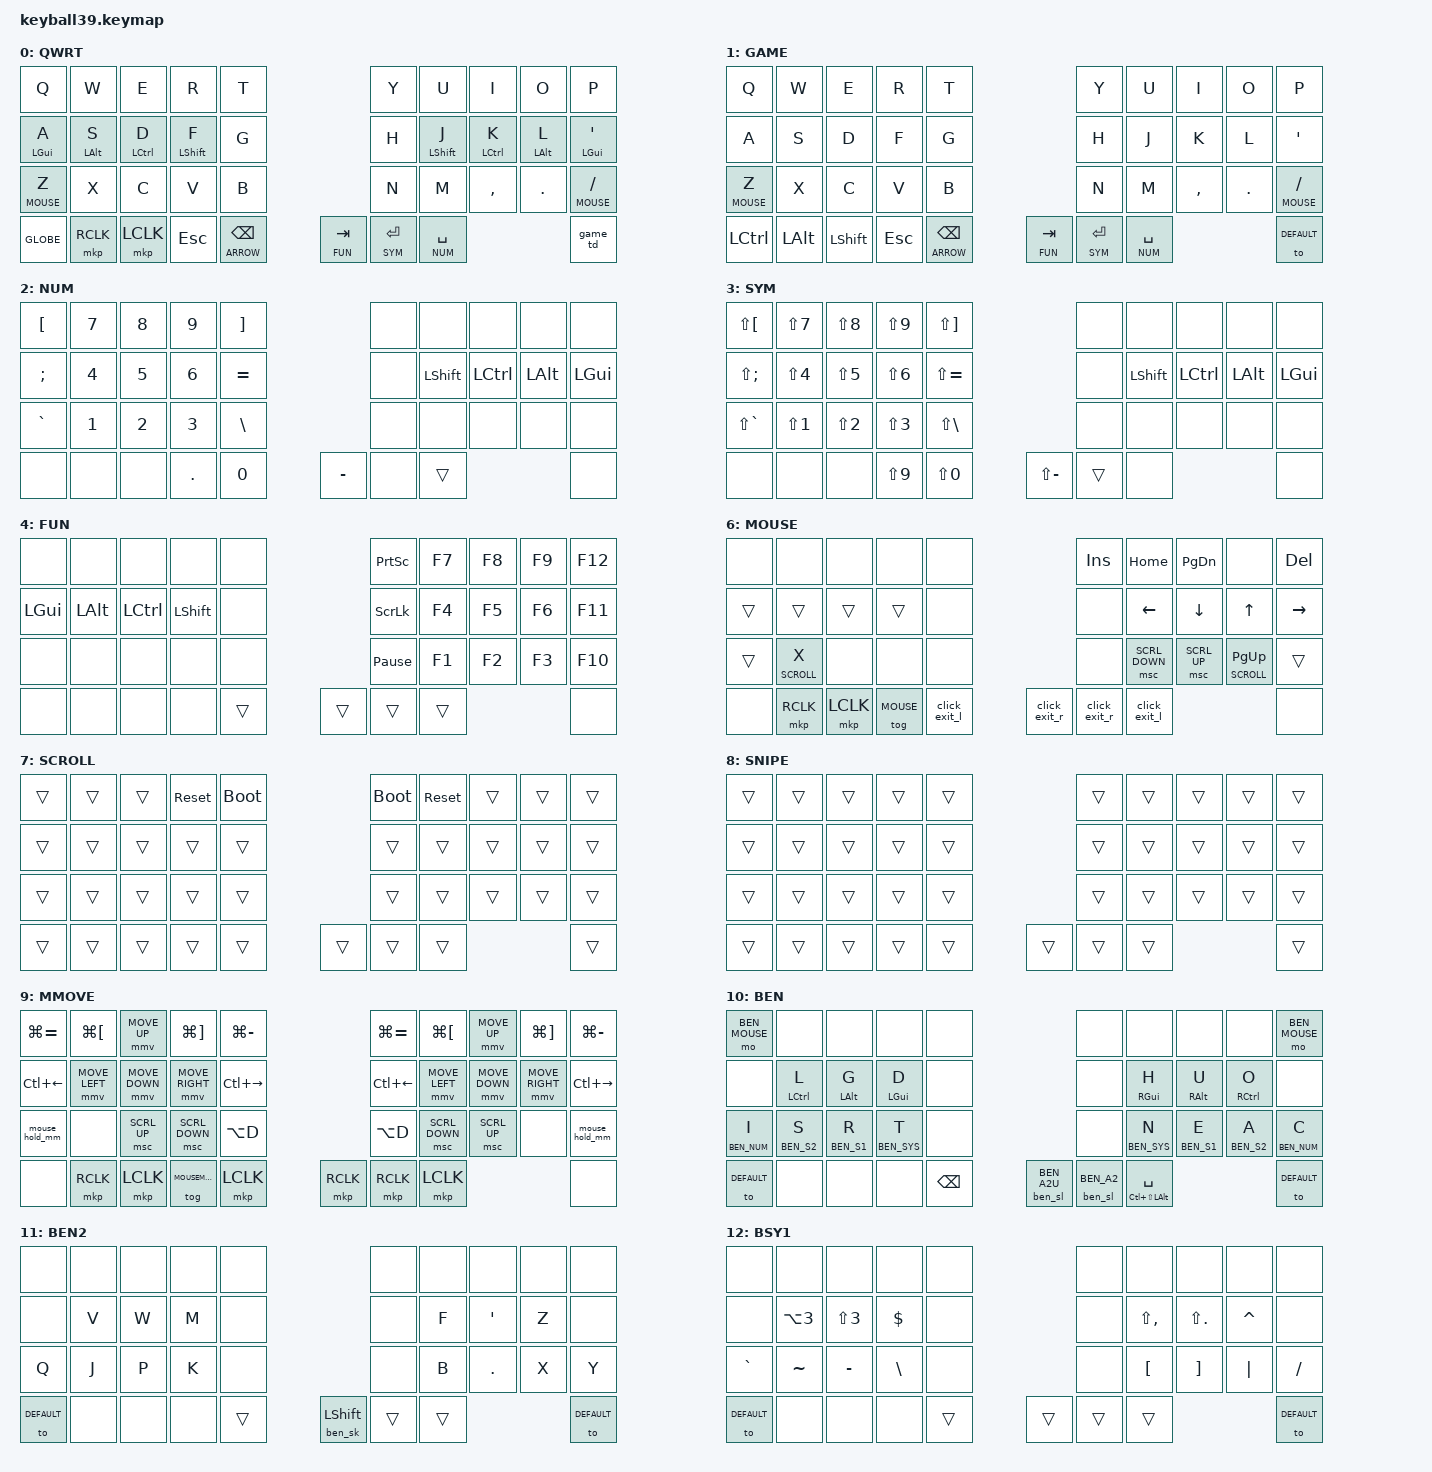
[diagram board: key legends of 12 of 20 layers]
#define DEFAULT 0
#define GAME    1
#define NUM     2
#define SYM     3
#define FUN     4
#define ARROW   5
#define MOUSE   6
#define SCROLL  7
#define SNIPE   8
#define MOUSEMOVE 9

// ── Ben Vallack "Piano" profile ────────────────────────────────────────
// A complete 18-key alternative layout living on layers 10-17, ported
// from benvallack/zmk-config-piano. It uses only 7 finger keys per hand
// (left S D F Z X C V, right J K L M , . /) plus 4 thumbs; every other
// position is &none so nothing bleeds through from QWRT.
//
// The alphabet is SPLIT: the 14 commonest letters (etaoinsrhldcug — ~85%
// of English) sit on BEN itself, the remaining 12 on BEN_A2, reached by
// a sticky-layer tap of the right outer thumb. Sub-layers are held from
// the bottom row exactly as Ben has them.
//
// Enter: triple-tap position 38. Exit: single tap of 38 (or 30).
#define BEN      10   // alpha1  — the 14 common letters + homerow mods
#define BEN_A2   11   // alpha2  — the 12 rare letters, via sticky layer
#define BEN_S1   12   // sym1    — hold C / ,
#define BEN_S2   13   // sym2    — hold X / .
#define BEN_NUM  14   // num     — hold Z / /
#define BEN_SYS  15   // sys     — hold V / M  (nav, editing, clicks)
#define BEN_BT   16   // bt      — bluetooth + &bootloader
#define BEN_A2U  17   // alpha2 shifted — capitals of the rare letters
#define BEN_MOUSE 18  // mouse    — hold Q / P, or the Q+W / O+P chord
#define BEN_SCRL  19  // scroll   — from BEN_MOUSE, hold W / O

// NOTE: BEN_SCRL is duplicated as a #define in keyball39_right.overlay,
// where it is listed in the trackball's scroll-layers. The two must stay
// in sync — the overlay cannot see this file's defines.

// Override max mouse cursor speed for &mmv (default 600 — tuned for 4K).
// Bumped from 1500 → 2100 (+40%) to match Delta Omega's "big-monitor
// reach" tuning. Drop back to 1500/600 if too fast. Must precede
// <dt-bindings/zmk/pointing.h>.
#define ZMK_POINTING_DEFAULT_MOVE_VAL 2100

// &msc scroll magnitude per tick (ZMK default 10).
//
// Was 20, which made Safari jump rather than scroll. The old comment here
// claimed CONFIG_ZMK_POINTING_SMOOTH_SCROLLING would render this
// high-resolution and let macOS smooth it. That is not what the code does,
// so the magnitude has to be right on its own:
//
//   1. zmk/app/src/pointing/resolution_multipliers.c defaults the wheel
//      multiplier to 15, and input_listener.c computes div = 16 - wheel.
//      15 -> div == 1, i.e. NO scaling at all unless the host negotiates a
//      different multiplier via a HID Feature report.
//   2. apply_resolution_scaling() in input_listener.c computes the divided
//      value and then discards it:
//          int16_t scaled = val / (int16_t)div;
//          *remainder = val - (scaled * (int16_t)div);
//          evt->value = val;      // <- unscaled; `scaled` is dead
//      So even with a cooperating host it never attenuates. Upstream ZMK,
//      not this config.
//
// SCRL_VAL is WHEEL EVENTS PER SECOND, not a magnitude. behavior_input_two_axis.c
// accumulates speed * trigger_period_ms/1000 per tick and emits only when the
// accumulator crosses 1.0, so the emitted value is always +/-1 and the rate is
// exactly SCRL_VAL.
//
// That matters because macOS supplies the smoothing itself, via
// IOHIDScrollAccelerator::accelerate() — a polynomial in the INTER-EVENT GAP:
//     8ms -> 1.386    16ms -> 1.276    50ms -> 0.849    125ms -> 0.156
// ~815x collapse from 1ms to 150ms spacing. So event RATE is the whole game:
// closely spaced events get accelerated and blended into a glide, widely
// spaced ones are rendered as bare individual notches.
//
// Retuned for the patched HID descriptor. With macOS computing a scroll
// resolution of 85 instead of its 9.0 fallback, one wheel unit moves
// 9/85 as far — about 0.32 lines instead of 3. That is the whole point: the
// STEP is now ~9.4x finer, which is what smoothness actually is. Speed has to
// be bought back by raising the rate to match, since speed = rate x step.
//
//   before:  60 units/sec x 3.00 lines = 180 lines/sec, in 3-line steps
//   after:  552 units/sec x 0.32 lines = 175 lines/sec, in 0.32-line steps
//
// 552 is the user's requested +15% over the 480 that first felt right.
// trigger-period-ms below caps EVENT emission at 1000/period = 500/sec, so
// above 500 a fraction of ticks carry 2 units rather than 1. At 0.32 lines
// per unit that worst-case step is 0.64 lines — still 4.7x finer than the
// 3-line step we had before the descriptor fix, so the cost is negligible.
//
// CAVEAT — USB vs BLE. 480 reports/sec is comfortable over USB. Over BLE at
// the 7.5ms connection interval in keyball39.conf the practical ceiling is
// nearer 133/sec, so wireless scrolling will be roughly a quarter this speed.
// If that bites, raise the connection interval or accept a slower wireless
// scroll — the smoothness is unaffected either way, only the speed.
#define ZMK_POINTING_DEFAULT_SCRL_VAL 552

#include <behaviors/mouse_keys.dtsi>
#include <dt-bindings/zmk/mouse.h>
#include <behaviors.dtsi>
#include <dt-bindings/zmk/keys.h>
#include <dt-bindings/zmk/bt.h>
#include <dt-bindings/zmk/pointing.h>
#include <input/processors.dtsi>

// Layer-taps: matches QMK LT() defaults on the Charybdis (tap-preferred
// semantics, 200ms term, 200ms quick-tap-repeat).
&lt {
    tapping-term-ms = <200>;
    flavor = "tap-preferred";
    quick-tap-ms = <200>;
};

// Default &mt override. NOTE: the home-row mods do NOT use &mt — they use
// the dedicated hm_* hold-taps below. This block only affects any bare
// `&mt` bindings (currently none). DANGER averted: stock ZMK &mt is
// hold-preferred (fires mod on next keypress — the opposite of the
// Charybdis feel), so this override pins it to the same Charybdis-parity
// values as the hm_* behaviors in case a bare &mt is ever added.
&mt {
    tapping-term-ms = <200>;
    flavor = "tap-preferred";
    quick-tap-ms = <200>;
};

&msc {
    // These two only do anything because SMOOTH_SCROLLING is off — with it on,
    // get_acceleration_exponent() force-returns 0 for the wheel axes and
    // speed() short-circuits to max_speed. See keyball39_right.conf.
    acceleration-exponent = <1>;  // linear ramp in, then constant
    // Ease-in for held scrolling. exponent 1 is LINEAR: speed = max * t/ttms,
    // starting from ZERO — ZMK has no floor parameter, so you cannot say
    // "start at 70%". A longer ramp therefore buys ease-in at the cost of
    // lead-in, because the accumulator must still reach 1.0 before the first
    // detent is emitted, at T = sqrt(2*ttms/SCRL_VAL).
    //
    // The scale here is SECONDS, not milliseconds. 40/150/200ms all felt
    // identical — a fifth of a second is below the threshold of noticing, so
    // scrolling appeared to start at full speed no matter what. Full speed is
    // 60 detents/sec, roughly 180 lines/sec at the macOS default of 3
    // lines/detent, so a 300ms "tap" at ttms=200 was already covering a page.
    //
    //   ttms   1st detent   detents by 0.2s / 0.4s / 1.0s / 2.0s
    //    200      82 ms        6.0 / 18.0 / 54.0 / 114.0   (felt instant)
    //   1500     224 ms        0.8 /  3.2 / 20.0 /  75.0   <- here
    //
    // Deliberate consequence: a press SHORTER THAN ~224ms now emits nothing
    // at all, because cumulative counts are max*T^2/(2*ttms) and that is
    // below 1.0. A flick no longer jumps the page; it does nothing. Scrolling
    // is now something you hold, not something you tap. If short taps need to
    // work again, lower this — the lead-in falls as sqrt(ttms).
    time-to-max-speed-ms = <1500>;
    // 2ms. The ceiling on emitted events is 1000/trigger-period, so 8ms
    // capped us at 125/sec — far below the 480/sec the finer step size now
    // needs. NB this Mac reports HIDMouseScrollAcceleration = 0, so macOS
    // applies a single linear segment rather than its gap-based accelerator
    // curve; rate buys smoothness directly here, not via OS acceleration.
    trigger-period-ms = <2>;
    delay-ms = <0>;
};

// Keyboard-driven mouse cursor (&mmv MOVE_* on the MOUSE layer).
// Defaults from urob/zmk-config — gentle ramp for fine control.
// Knobs:
//   acceleration-exponent: 0=constant speed, 1=quadratic (smooth), higher=more aggressive
//   time-to-max-speed-ms:  higher = more precision on short taps, lower = snappier traversal
//   delay-ms:              dead time before motion starts (keep 0)
// Max speed itself is set by ZMK_POINTING_DEFAULT_MOVE_VAL (default 600);
// override with `#define ZMK_POINTING_DEFAULT_MOVE_VAL <n>` before pointing.h
// if you find max traversal too slow/fast for your display resolution.
&mmv {
    acceleration-exponent = <1>;
    time-to-max-speed-ms = <500>;
    delay-ms = <0>;
};

&caps_word { continue-list = <UNDERSCORE MINUS>; };

/ {
    // custom shift using mod-morph

    combos {
        compatible = "zmk,combos";

        // Toggle the MOUSEMOVE layer with a two-finger chord.
        // Restricted to <DEFAULT MOUSEMOVE> so a stray S+D / K+L on
        // other layers (NUM, SYM, ARROW, etc.) doesn't fire &tog
        // MOUSEMOVE — same defensive pattern Delta Omega's TODO calls
        // out around combo layer-filter interference.
        // Left hand: S + D. Right hand: K + L.
        // NOTE: on MMOVE, S and D are MOVE_LEFT / MOVE_DOWN. A deliberate
        // simultaneous S+D tap exits the layer; normal diagonal movement
        // (press S, then add D >25ms later, holding) does not.
        combo_sd_mmove {
            timeout-ms = <25>;
            require-prior-idle-ms = <250>;
            key-positions = <11 12>; // S + D
            bindings = <&tog MOUSEMOVE>;
            layers = <DEFAULT MOUSEMOVE>;
        };
        combo_right_mousemove {
            timeout-ms = <25>;
            require-prior-idle-ms = <250>;
            key-positions = <17 18>; // K + L
            bindings = <&tog MOUSEMOVE>;
            layers = <DEFAULT MOUSEMOVE>;
        };

        // Lock MOUSE on via one-handed two-finger chord. Restricted to
        // <DEFAULT MOUSE> for the same reason as the MOUSEMOVE combos.
        // Z and / are already &lt MOUSE — holding momentarily activates
        // MOUSE; the combo is the "stay there" path. Click bindings on
        // MOUSE call &tog MOUSE (via the click_exit_* macros) so
        // clicking exits the lock.
        combo_left_mouse {
            timeout-ms = <25>;
            require-prior-idle-ms = <250>;
            key-positions = <20 21>; // Z + X
            bindings = <&tog MOUSE>;
            layers = <DEFAULT MOUSE>;
        };
        combo_right_mouse {
            timeout-ms = <25>;
            require-prior-idle-ms = <250>;
            key-positions = <28 29>; // . + /
            bindings = <&tog MOUSE>;
            layers = <DEFAULT MOUSE>;
        };
        // Same chords FROM MMOVE: lock MOUSE on and drop MMOVE
        // underneath, so when MOUSE later exits (click / ESC-position)
        // you land on QWRT, not back in MMOVE. Mirrors the QWRT-side
        // muscle memory (Z+X / .+/) inside the mouse-move layer.
        combo_left_mouse_mm {
            timeout-ms = <25>;
            require-prior-idle-ms = <250>;
            key-positions = <20 21>; // Z + X (on MMOVE)
            bindings = <&mouse_lock_mm>;
            layers = <MOUSEMOVE>;
        };
        combo_right_mouse_mm {
            timeout-ms = <25>;
            require-prior-idle-ms = <250>;
            key-positions = <28 29>; // . + / (on MMOVE)
            bindings = <&mouse_lock_mm>;
            layers = <MOUSEMOVE>;
        };

        // Horizontal scroll chords on MMOVE — 4 directions from 3 keys
        // per hand. Rule: "lean the pair toward the direction":
        //   left hand:  X+C = scroll left,  C+V = scroll right
        //   right hand: M+, = scroll left,  ,+. = scroll right
        // Hold the chord to keep scrolling (same as the 3-finger
        // combos). No require-prior-idle — MMOVE is a nav layer, no
        // typing rolls to guard against, and an idle gate would block
        // chording right after a vertical scroll. 50ms window for an
        // easy deliberate two-finger press. (Copy/paste X+C / C+V
        // combos are QWRT-only now; on MMOVE these positions scroll.
        // X+V cut, D+F del, A+S select-all still work on MMOVE.)
        combo_hscroll_left_l {
            timeout-ms = <50>;
            key-positions = <21 22>; // X + C (on MMOVE)
            bindings = <&msc SCRL_LEFT>;
            layers = <MOUSEMOVE>;
        };
        combo_hscroll_right_l {
            timeout-ms = <50>;
            key-positions = <22 23>; // C + V (on MMOVE)
            bindings = <&msc SCRL_RIGHT>;
            layers = <MOUSEMOVE>;
        };
        combo_hscroll_left_r {
            timeout-ms = <50>;
            key-positions = <26 27>; // M + , (on MMOVE)
            bindings = <&msc SCRL_LEFT>;
            layers = <MOUSEMOVE>;
        };
        combo_hscroll_right_r {
            timeout-ms = <50>;
            key-positions = <27 28>; // , + . (on MMOVE)
            bindings = <&msc SCRL_RIGHT>;
            layers = <MOUSEMOVE>;
        };

        // Three-finger scroll combos, active on QWRT and MMOVE. Looser
        // 50ms window than the 2-key combos — a 3-key chord is harder
        // to land simultaneously, and rolling three specific keys
        // mid-typing is unlikely, so the wider window is safe.
        // require-prior-idle-ms 250 still blocks it during a typing
        // burst. Held: all three keys down keeps &msc scrolling;
        // release any one to stop. Both hands, mirrored:
        //   right: U+I+O up, M+,+. down
        //   left:  W+E+R up, X+C+V down
        // NOTE: X+C+V is a superset of the copy/paste/cut 2-key combos,
        // so those pick up ~50ms standalone activation latency (the
        // resolver waits out X+C+V's candidacy window). Accepted
        // tradeoff. W+E+R has no such overlap.
        combo_scroll_up {
            timeout-ms = <50>;
            require-prior-idle-ms = <250>;
            key-positions = <6 7 8>;     // U + I + O
            bindings = <&msc SCRL_UP>;
            layers = <DEFAULT>;
        };
        combo_scroll_down {
            timeout-ms = <50>;
            require-prior-idle-ms = <250>;
            key-positions = <26 27 28>;  // M + , + .
            bindings = <&msc SCRL_DOWN>;
            layers = <DEFAULT>;
        };
        combo_scroll_up_left {
            timeout-ms = <50>;
            require-prior-idle-ms = <250>;
            key-positions = <1 2 3>;     // W + E + R
            bindings = <&msc SCRL_UP>;
            layers = <DEFAULT>;
        };
        combo_scroll_down_left {
            timeout-ms = <50>;
            require-prior-idle-ms = <250>;
            key-positions = <21 22 23>;  // X + C + V
            bindings = <&msc SCRL_DOWN>;
            layers = <DEFAULT>;
        };

        // Two-key action combos. 25ms window (the standard 2-key combo
        // timing here) + require-prior-idle-ms 250 so they can't fire
        // mid-typing-burst.
        //   - ESC combos (Q+W, J+K): DEFAULT only.
        //   - Editing combos (D+F del, A+S select-all, X+C copy,
        //     C+V paste, X+V cut): DEFAULT + MOUSEMOVE, so they're
        //     reachable while in the mouse-move layer too.
        //
        // J+K consistently fires ESC across DEFAULT and MMOVE — two
        // combos with the same positions, one per layer. Ported from
        // Delta Omega: the MMOVE variant USED to fire &tog MOUSEMOVE
        // (combo_exit_mmove_jk), but having J+K mean two different
        // things on different layers was inconsistent. Exit MMOVE via
        // S+D or K+L combos, or the ESC-position thumb key.
        combo_esc_qw {
            timeout-ms = <25>;
            require-prior-idle-ms = <250>;
            key-positions = <0 1>;       // Q + W
            bindings = <&kp ESC>;
            layers = <DEFAULT>;
        };
        combo_esc_jk {
            timeout-ms = <25>;
            require-prior-idle-ms = <250>;
            key-positions = <16 17>;     // J + K
            bindings = <&kp ESC>;
            layers = <DEFAULT>;
        };
        combo_esc_mmove_jk {
            timeout-ms = <25>;
            require-prior-idle-ms = <250>;
            key-positions = <16 17>;     // J + K (on MMOVE → also ESC)
            bindings = <&kp ESC>;
            layers = <MOUSEMOVE>;
        };
        combo_del_df {
            timeout-ms = <25>;
            require-prior-idle-ms = <250>;
            key-positions = <12 13>;     // D + F
            bindings = <&kp DEL>;
            layers = <DEFAULT MOUSEMOVE>;
        };
        // Select-all (Cmd+A) on A+S. Both A+S and S+D are subsets of
        // the A+S+D caps_word combo — the resolver still picks the
        // 2-key combo correctly when the 3rd key isn't pressed, but
        // with ~50ms latency (it waits out caps_word's candidacy
        // window). Acceptable: neither is speed-critical, and pressing
        // all of A+S+D fires caps_word cleanly.
        combo_select_all_as {
            timeout-ms = <25>;
            require-prior-idle-ms = <250>;
            key-positions = <10 11>;     // A + S
            bindings = <&kp LG(A)>;
            layers = <DEFAULT MOUSEMOVE>;
        };
        combo_copy_xc {
            timeout-ms = <25>;
            require-prior-idle-ms = <250>;
            key-positions = <21 22>;     // X + C
            bindings = <&kp LG(C)>;
            layers = <DEFAULT>;
        };
        combo_paste_cv {
            timeout-ms = <25>;
            require-prior-idle-ms = <250>;
            key-positions = <22 23>;     // C + V
            bindings = <&kp LG(V)>;
            layers = <DEFAULT>;
        };
        combo_cut_xv {
            timeout-ms = <25>;
            require-prior-idle-ms = <250>;
            key-positions = <21 23>;     // X + V
            bindings = <&kp LG(X)>;
            layers = <DEFAULT MOUSEMOVE>;
        };

        // Three-key caps-word combo. A+S+D — position 10 (A) is unique
        // to this combo, so there's no subset/superset ambiguity with
        // any other combo. 50ms window (the >2-key standard here).
        // Fires &caps_word: the next word is shifted, auto-ends on
        // space/most punctuation (continue-list keeps it through - and _).
        combo_caps_word {
            timeout-ms = <50>;
            require-prior-idle-ms = <250>;
            key-positions = <10 11 12>;  // A + S + D
            bindings = <&caps_word>;
            layers = <DEFAULT>;
        };

        // === Ben "Piano" profile combos ===
        // Every one is gated to a BEN_* layer. ZMK matches a combo's
        // `layers` list against the HIGHEST active layer, so a combo
        // gated to BEN is automatically suppressed while a BEN sub-layer
        // is held — which is exactly what Ben's config relies on.
        ben_combo_sys {
            timeout-ms = <30>;
            key-positions = <16 17 18>;   // J + K + L
            bindings = <&to BEN_SYS>;
            layers = <BEN>;
        };
        ben_combo_caps {
            timeout-ms = <30>;
            key-positions = <26 27 28>;   // M + , + .
            bindings = <&caps_word>;
            layers = <BEN>;
        };
        // Escape hatch to the BT/bootloader layer: hold C (SYM1), then
        // chord , + . — this is the reflash path while living in BEN.
        ben_combo_bt {
            timeout-ms = <10>;
            key-positions = <27 28>;      // , + .
            bindings = <&to BEN_BT>;
            layers = <BEN_S1>;
        };
        // Mouse toggle from BEN. Z+X and .+/ are real letters here
        // (i+s and a+c), so the chord moves up to the unused top row —
        // same shape, same hands, one row higher.
        ben_combo_mouse_l {
            timeout-ms = <25>;
            require-prior-idle-ms = <250>;
            key-positions = <0 1>;        // Q + W
            bindings = <&tog BEN_MOUSE>;
            layers = <BEN>;
        };
        ben_combo_mouse_r {
            timeout-ms = <25>;
            require-prior-idle-ms = <250>;
            key-positions = <8 9>;        // O + P
            bindings = <&tog BEN_MOUSE>;
            layers = <BEN>;
        };
        // Horizontal scroll inside the Ben profile, identical in shape to the
        // MMOVE chords so there is only one thing to remember: the shared
        // middle key is the pivot and the neighbour you add picks the
        // direction. Z and SLASH stay clear as the layer escape.
        ben_combo_hscroll_left_l {
            timeout-ms = <50>;
            key-positions = <21 22>;      // X + C
            bindings = <&msc SCRL_LEFT>;
            layers = <BEN_MOUSE>;
        };
        ben_combo_hscroll_right_l {
            timeout-ms = <50>;
            key-positions = <22 23>;      // C + V
            bindings = <&msc SCRL_RIGHT>;
            layers = <BEN_MOUSE>;
        };
        ben_combo_hscroll_left_r {
            timeout-ms = <50>;
            key-positions = <26 27>;      // M + ,
            bindings = <&msc SCRL_LEFT>;
            layers = <BEN_MOUSE>;
        };
        ben_combo_hscroll_right_r {
            timeout-ms = <50>;
            key-positions = <27 28>;      // , + .
            bindings = <&msc SCRL_RIGHT>;
            layers = <BEN_MOUSE>;
        };
        ben_combo_lalt {
            timeout-ms = <20>;
            key-positions = <22 23>;      // C + V
            bindings = <&kp LALT>;
            layers = <BEN_SYS>;
        };
        ben_combo_lclk {
            timeout-ms = <20>;
            key-positions = <26 27>;      // M + ,
            bindings = <&mkp LCLK>;
            layers = <BEN_SYS>;
        };
        ben_combo_rclk {
            timeout-ms = <20>;
            key-positions = <16 17>;      // J + K
            bindings = <&mkp RCLK>;
            layers = <BEN_SYS>;
        };

    };

    behaviors {
        // === Home row mods — CHARYBDIS PARITY (QMK-default port) ===
        // The user's Charybdis Nano (QMK bkb-master @ 0.24.7, keymap
        // "cdmap") runs 100% stock QMK tap-hold: TAPPING_TERM 200,
        // QUICK_TAP_TERM 200, no PERMISSIVE_HOLD, no HOLD_ON_OTHER_KEY_
        // PRESS, no chordal/positional anything. Its feel — which the
        // user calls "absolutely spot on, perfect" — is ONE rule on
        // every finger:
        //
        //   Hold the key past 200ms -> modifier (any letters pressed in
        //   the meantime are queued and come out WITH the mod).
        //   Release before 200ms -> letters. Release order, roll
        //   direction, typing flow: all irrelevant. Pure timer.
        //
        // ZMK equivalent (verified line-by-line against QMK
        // action_tapping.c and ZMK behavior_hold_tap.c): flavor =
        // "tap-preferred", tapping-term-ms 200, quick-tap-ms 200, NO
        // require-prior-idle-ms, NO hold-trigger-key-positions, NO
        // hold-trigger-on-release. The earlier per-finger flavor mix +
        // 280-300ms terms + idle gates + cross-hand lists were the
        // source of "takes too long" / "missed capitals" / inconsistent
        // feel: the lists outright forced same-hand capitals (F held +
        // R) and same-hand chords (A held + C = Cmd+C) to TAP unless
        // the mod was held ALONE first, and the mixed flavors meant no
        // single muscle-memory rule worked everywhere.
        //
        // Capitals under parity: press F, press the letter any time,
        // keep F down until 200ms from F-down -> capital (the letter is
        // captured and replayed shifted). Same as the Charybdis.
        //
        // TWO deliberate non-parity islands (explicit user requests):
        //   hm_lalt (L): keeps a positions list of everything-except-D,
        //     so an L+D overlap inside the decision window can't fire
        //     Alt+D (= macOS dictation; the deliberate voice key lives
        //     on MMOVE). Hold L alone past 200ms then D still works.
        //   hm_apos ('): stays balanced + thumbs-only list + rpi 150 so
        //     '+Space = Cmd+Space (Spotlight) fires INSTANTLY on Space
        //     release, while '+letter can never mod (contractions safe).
        //
        // Tuning dial if mid-word linger-mods ever materialize: add
        // require-prior-idle-ms <100-150> to the NON-shift mods only
        // (QMK can't express it, but it only acts mid-burst). Ship
        // strict parity first.

        // S (LALT), D (LCTRL) — left hand.
        hm_l: home_row_mod_left {
            compatible = "zmk,behavior-hold-tap";
            #binding-cells = <2>;
            flavor = "tap-preferred";
            tapping-term-ms = <200>;
            quick-tap-ms = <200>;
            bindings = <&kp>, <&kp>;
        };
        // A (LGUI) — left pinky.
        hm_a: home_row_mod_a {
            compatible = "zmk,behavior-hold-tap";
            #binding-cells = <2>;
            flavor = "tap-preferred";
            tapping-term-ms = <200>;
            quick-tap-ms = <200>;
            // Veto list: every position EXCEPT 18 (L). Mirror of hm_lalt's
            // everything-except-D list (which blocks Alt+D dictation).
            //
            // Why: rolling "al" (all, also, always, total...) with A held past
            // the 200ms term resolved A as GUI, and GUI+L on the user's RDP'd
            // Windows box is Win+L — instant session lock. With 18 omitted,
            // an L that arrives while A is still undecided FORBIDS the hold,
            // so it resolves as tap and emits the literal "al" instead.
            //
            // A veto can only cancel holds, never create them, so every other
            // GUI chord (Cmd+S, Cmd+C, Win+anything) is unaffected. Deliberate
            // Cmd+L (macOS address bar) still works: hold A alone past 200ms
            // FIRST, then tap L — by then the hold is already decided and the
            // list is never consulted.
            //
            // Do NOT add hold-trigger-on-release here: with tap-preferred the
            // decision fires on the timer, before releases are processed, so
            // on-release leaves position_of_first_other_key_pressed at -1 and
            // silently defeats this list (bitten by this before).
            hold-trigger-key-positions = <0 1 2 3 4 5 6 7 8 9 10 11 12 13 14 15 16 17 19 20 21 22 23 24 25 26 27 28 29 30 31 32 33 34 35 36 37 38>;
            bindings = <&kp>, <&kp>;
        };
        // K (LCTRL) — right hand.
        hm_r: home_row_mod_right {
            compatible = "zmk,behavior-hold-tap";
            #binding-cells = <2>;
            flavor = "tap-preferred";
            tapping-term-ms = <200>;
            quick-tap-ms = <200>;
            bindings = <&kp>, <&kp>;
        };
        // L (LALT) — non-parity island #1: list = everything except D
        // (pos 12) so an L+D overlap in the window can't fire Alt+D
        // (dictation). See header comment.
        hm_lalt: home_row_mod_l_alt {
            compatible = "zmk,behavior-hold-tap";
            #binding-cells = <2>;
            flavor = "tap-preferred";
            tapping-term-ms = <200>;
            quick-tap-ms = <200>;
            hold-trigger-key-positions = <0 1 2 3 4 5 6 7 8 9 10 11 13 14 15 16 17 18 19 20 21 22 23 24 25 26 27 28 29 30 31 32 33 34 35 36 37 38>;
            bindings = <&kp>, <&kp>;
        };
        // ' (LGUI) — non-parity island #2: balanced + a curated list.
        // Listed keys resolve Cmd INSTANTLY (on the key's release, like
        // Spotlight); everything else is forced to tap. List = thumbs
        // (30-38, '+Space Spotlight) + the left-hand edit cluster the
        // user chords through ' all day:
        //   10=A select-all, 13=F find, 20=Z undo, 21=X cut,
        //   22=C copy, 23=V paste
        // These are the letters that (almost) never follow an apostrophe
        // in English. The real contraction letters stay OUT and can
        // never mod: S('s), T('t), D('d), R/E('re), M('m), L('ll).
        // Edge words ("I've", "o'clock", "y'all") are still protected
        // in-flow by require-prior-idle-ms 150 — mid-word, ' is forced
        // to tap before the list is even consulted.
        hm_apos: home_row_mod_apos {
            compatible = "zmk,behavior-hold-tap";
            #binding-cells = <2>;
            flavor = "balanced";
            tapping-term-ms = <200>;
            quick-tap-ms = <200>;
            require-prior-idle-ms = <150>;
            hold-trigger-on-release;
            hold-trigger-key-positions = <10 13 20 21 22 23 30 31 32 33 34 35 36 37 38>;
            bindings = <&kp>, <&kp>;
        };
        // F, J (LSHFT) — same tap-preferred timer as the other mods but
        // with a PER-FINGER shorter term: 170ms instead of 200.
        // Rationale: the user hits shift very rapidly and was releasing
        // F/J just before the 200ms mark -> "fi" instead of "I".
        // Index fingers are the fastest fingers; sunaku's Glorious
        // Engrammer ships index=180 on tap-preferred; user opted one
        // notch below. 170 rescues releases in the 170-200ms band
        // where the misses live.
        // Tuning ladder if "fi" persists: 160 next, 150 is the hard
        // floor (below that, a slow deliberate 'f' letter-tap starts
        // registering as Shift and plain letters get dropped).
        hm_shift_l: hm_shift_left {
            compatible = "zmk,behavior-hold-tap";
            #binding-cells = <2>;
            flavor = "tap-preferred";
            tapping-term-ms = <170>;
            quick-tap-ms = <200>;
            bindings = <&kp>, <&kp>;
        };
        hm_shift_r: hm_shift_right {
            compatible = "zmk,behavior-hold-tap";
            #binding-cells = <2>;
            flavor = "tap-preferred";
            tapping-term-ms = <170>;
            quick-tap-ms = <200>;
            bindings = <&kp>, <&kp>;
        };

        // GAME-layer entry guarded by double-tap. Position 38 was firing
        // accidentally from palm/pinky brushes — single tap now no-ops,
        // two taps within 250ms enter GAME. Exit (in game_layer) is still
        // single-tap so leaving the layer is friction-free.
        game_td: game_tap_dance {
            compatible = "zmk,behavior-tap-dance";
            #binding-cells = <0>;
            tapping-term-ms = <250>;
            bindings = <&none>, <&to GAME>, <&to BEN>;
        };

        // === Ben "Piano" profile behaviors ===
        // Verbatim timings from benvallack/zmk-config-piano, kept in
        // their own ben_* namespace so the Charybdis-parity tuning on
        // the QWRT homerow mods above is left completely alone.
        //
        // NB hold-tap parameter order is <hold>, <tap> — so
        // `&ben_td Q BSPC` is hold=Q, TAP=backspace.
        ben_hm_l: ben_homerow_mod_left {
            compatible = "zmk,behavior-hold-tap";
            #binding-cells = <2>;
            tapping-term-ms = <300>;
            quick-tap-ms = <250>;
            flavor = "tap-preferred";
            bindings = <&kp>, <&kp>;
        };
        ben_hm_r: ben_homerow_mod_right {
            compatible = "zmk,behavior-hold-tap";
            #binding-cells = <2>;
            tapping-term-ms = <300>;
            quick-tap-ms = <250>;
            flavor = "tap-preferred";
            bindings = <&kp>, <&kp>;
        };
        ben_hl_l: ben_homerow_layer_left {
            compatible = "zmk,behavior-hold-tap";
            #binding-cells = <2>;
            tapping-term-ms = <220>;
            quick-tap-ms = <250>;
            flavor = "tap-preferred";
            bindings = <&mo>, <&kp>;
        };
        ben_hl_r: ben_homerow_layer_right {
            compatible = "zmk,behavior-hold-tap";
            #binding-cells = <2>;
            tapping-term-ms = <220>;
            quick-tap-ms = <250>;
            flavor = "tap-preferred";
            bindings = <&mo>, <&kp>;
        };
        // hold = shift, tap = jump back to the BEN alpha layer.
        ben_sr: ben_shift_layer {
            compatible = "zmk,behavior-hold-tap";
            #binding-cells = <2>;
            tapping-term-ms = <300>;
            quick-tap-ms = <0>;
            flavor = "tap-preferred";
            bindings = <&kp>, <&to>;
            retro-tap;
        };
        ben_td: ben_tapdance {
            compatible = "zmk,behavior-hold-tap";
            #binding-cells = <2>;
            tapping-term-ms = <190>;
            quick-tap-ms = <250>;
            flavor = "tap-preferred";
            bindings = <&kp>, <&kp>;
        };
        // Local sticky key so Ben's 2s window doesn't mutate the global
        // &sk that the QWRT profile may want later.
        ben_sk: ben_sticky_key {
            compatible = "zmk,behavior-sticky-key";
            #binding-cells = <1>;
            bindings = <&kp>;
            release-after-ms = <2000>;
            quick-release;
        };
        // Sticky LAYER for the alpha2 hop. Stock &sl expires after
        // 1000ms; that is fine once the layout is in muscle memory but
        // brutal while learning — overrun the window and the sticky
        // layer has already dropped, so you silently get the alpha1
        // letter instead of the alpha2 one you meant. 2000ms matches the
        // window Ben picked for his own sticky key. Drop it back to
        // 1000 once the layout is fluent.
        ben_sl: ben_sticky_layer {
            compatible = "zmk,behavior-sticky-key";
            #binding-cells = <1>;
            bindings = <&mo>;
            release-after-ms = <2000>;
            quick-release;
        };
    };

    macros {
        // Click-and-exit-MOUSE macros.
        //
        // MOUSE is entered explicitly (hold Z/SLASH via &lt, or the
        // z+x / .+/ combos which &tog it on). These macros make clicks
        // terminal: send the click, hold it for the duration the key is
        // held (so drag works), and on release fire &tog MOUSE to drop
        // the layer. Combined with the combos, the model is "enter →
        // act → click exits."
        click_exit_l: click_exit_left {
            compatible = "zmk,behavior-macro";
            #binding-cells = <0>;
            bindings
                = <&macro_press &mkp LCLK>
                , <&macro_pause_for_release>
                , <&macro_release &mkp LCLK>
                , <&tog MOUSE>
                ;
        };
        click_exit_r: click_exit_right {
            compatible = "zmk,behavior-macro";
            #binding-cells = <0>;
            bindings
                = <&macro_press &mkp RCLK>
                , <&macro_pause_for_release>
                , <&macro_release &mkp RCLK>
                , <&tog MOUSE>
                ;
        };

        // MMOVE -> MOUSE handoff keys (bound on MMOVE Z and /).
        // Hold: drop out of MMOVE, momentarily activate MOUSE; on
        // release, fall through to QWRT — mirroring the QWRT-side
        // "hold Z / hold SLASH for MOUSE" muscle memory from inside
        // the mouse-move layer. A quick tap = exit MMOVE to QWRT
        // (brief MOUSE blip, harmless).
        mouse_hold_mm: mouse_hold_from_mmove {
            compatible = "zmk,behavior-macro";
            #binding-cells = <0>;
            bindings
                = <&macro_tap &tog MOUSEMOVE>
                , <&macro_press &mo MOUSE>
                , <&macro_pause_for_release>
                , <&macro_release &mo MOUSE>
                ;
        };
        // Z+X / .+/ chord from MMOVE: lock MOUSE on and turn MMOVE
        // off underneath — exiting MOUSE later (click / ESC-position)
        // lands on QWRT.
        mouse_lock_mm: mouse_lock_from_mmove {
            compatible = "zmk,behavior-macro";
            #binding-cells = <0>;
            bindings = <&macro_tap &tog MOUSEMOVE &tog MOUSE>;
        };
    };

    keymap {
        compatible = "zmk,keymap";

        default_layer {
            label = "QWRT";
            bindings = <
&kp Q       &kp W       &kp E        &kp R        &kp T                                    &kp Y          &kp U          &kp I        &kp O       &kp P
&hm_a LGUI A  &hm_l LALT S  &hm_l LCTRL D  &hm_shift_l LSHFT F  &kp G                        &kp H  &hm_shift_r LSHFT J  &hm_r LCTRL K  &hm_lalt LALT L  &hm_apos LGUI APOS
&lt MOUSE Z &kp X       &kp C        &kp V        &kp B                                    &kp N          &kp M          &kp COMMA    &kp DOT     &lt MOUSE SLASH
&kp GLOBE   &mkp RCLK   &mkp LCLK    &kp ESC      &lt ARROW BACKSPACE  &lt FUN TAB         &lt SYM ENTER  &lt NUM SPACE                           &game_td
            >;
        };

        game_layer {
            label = "GAME";
            bindings = <
&kp Q         &kp W     &kp E        &kp R        &kp T                                    &kp Y          &kp U          &kp I        &kp O       &kp P
&kp A         &kp S     &kp D        &kp F        &kp G                                    &kp H          &kp J          &kp K        &kp L       &kp APOS
&lt MOUSE Z   &kp X     &kp C        &kp V        &kp B                                    &kp N          &kp M          &kp COMMA    &kp DOT     &lt MOUSE SLASH
&kp LCTRL     &kp LALT  &kp LSHFT    &kp ESC      &lt ARROW BACKSPACE  &lt FUN TAB         &lt SYM ENTER  &lt NUM SPACE                           &to DEFAULT
            >;
        };

        number_layer {
            label = "NUM";
            bindings = <
&kp LEFT_BRACKET  &kp NUMBER_7  &kp NUMBER_8  &kp NUMBER_9  &kp RIGHT_BRACKET                    &none   &none      &none      &none     &none
&kp SEMI          &kp NUMBER_4  &kp NUMBER_5  &kp NUMBER_6  &kp EQUAL                            &none   &kp LSHFT  &kp LCTRL  &kp LALT  &kp LGUI
&kp GRAVE         &kp NUMBER_1  &kp NUMBER_2  &kp NUMBER_3  &kp BACKSLASH                        &none   &none      &none      &none     &none
&none             &none         &none         &kp PERIOD    &kp NUMBER_0   &kp MINUS             &none  &trans                           &none
            >;
        };

        symbol_layer {
            label = "SYM";
            bindings = <
&kp LS(LEFT_BRACKET)  &kp LS(NUMBER_7)  &kp LS(NUMBER_8)  &kp LS(NUMBER_9)  &kp LS(RIGHT_BRACKET)                         &none  &none      &none      &none     &none
&kp LS(SEMI)          &kp LS(NUMBER_4)  &kp LS(NUMBER_5)  &kp LS(NUMBER_6)  &kp LS(EQUAL)                                 &none  &kp LSHFT  &kp LCTRL  &kp LALT  &kp LGUI
&kp LS(GRAVE)         &kp LS(NUMBER_1)  &kp LS(NUMBER_2)  &kp LS(NUMBER_3)  &kp LS(BACKSLASH)                             &none  &none      &none      &none     &none
&none                 &none             &none             &kp LS(NUMBER_9)  &kp LS(NUMBER_0)       &kp LS(MINUS)          &trans &none                           &none
            >;
        };

        function_layer {
            label = "FUN";
            bindings = <
&none     &none     &none      &none      &none                 &kp PRINTSCREEN  &kp F7  &kp F8  &kp F9  &kp F12
&kp LGUI  &kp LALT  &kp LCTRL  &kp LSHFT  &none                 &kp SCROLLLOCK   &kp F4  &kp F5  &kp F6  &kp F11
&none     &none     &none      &none      &none                 &kp PAUSE_BREAK  &kp F1  &kp F2  &kp F3  &kp F10
&none     &none     &none      &none      &trans  &trans        &trans           &trans                  &none
            >;
        };

        arrow_layer {
            label = "ARROW";
            bindings = <
&trans    &trans               &trans     &trans              &bt BT_CLR             &bt BT_SEL 0  &bt BT_SEL 1  &bt BT_SEL 2  &bt BT_SEL 3  &bt BT_SEL 4
&kp LGUI  &kp LALT             &kp LCTRL  &kp LSHFT           &none                  &kp LEFT      &kp LEFT      &kp DOWN      &kp UP        &kp RIGHT
&trans    &kp K_VOLUME_DOWN    &kp K_MUTE &kp K_VOLUME_UP     &kp LC(LS(LA(LG(M))))  &kp INS       &kp HOME      &kp PG_DN     &kp PG_UP     &kp END
&trans    &trans               &trans     &trans              &trans  &trans         &trans  &trans                                          &trans
            >;
        };

        mouse_layer {
            label = "MOUSE";
            bindings = <
&none   &none   &none   &none      &none                            &kp INS    &kp HOME      &kp PAGE_DOWN  &none               &kp DEL
&trans  &trans  &trans  &trans     &none                            &none      &kp LEFT      &kp DOWN       &kp UP              &kp RIGHT
&trans  &lt SCROLL X  &none   &none      &none                       &none      &msc SCRL_DOWN  &msc SCRL_UP  &lt SCROLL PAGE_UP  &trans
&none   &mkp RCLK  &mkp LCLK  &tog MOUSE  &click_exit_l  &click_exit_r     &click_exit_r  &click_exit_l                     &none
            >;
        };

        scroll_layer {
            label = "SCROLL";
            bindings = <
&trans    &trans  &trans  &sys_reset  &bootloader          &bootloader   &sys_reset  &trans  &trans  &trans
&trans    &trans  &trans  &trans     &trans               &trans        &trans     &trans  &trans  &trans
&trans    &trans  &trans  &trans     &trans               &trans        &trans     &trans  &trans  &trans
&trans    &trans  &trans  &trans     &trans      &trans   &trans        &trans                     &trans
            >;
        };

        snipe_layer {
            label = "SNIPE";
            bindings = <
&trans  &trans  &trans  &trans  &trans                       &trans  &trans  &trans  &trans  &trans
&trans  &trans  &trans  &trans  &trans                       &trans  &trans  &trans  &trans  &trans
&trans  &trans  &trans  &trans  &trans                       &trans  &trans  &trans  &trans  &trans
&trans  &trans  &trans  &trans  &trans &trans                &trans  &trans                  &trans
            >;
        };

        // Two-handed keyboard mouse layer. Entered/exited via combos:
        //   left hand:  S + D together (after 250ms idle, 25ms timeout)
        //   right hand: K + L together (same)
        //   also exits: the ESC-position thumb key
        // (J + K on MMOVE now fires ESC, matching its DEFAULT behavior —
        // ported from Delta Omega for cross-layer consistency.)
        // Inverted-T movement clusters on each hand:
        //   left:  E=up, S=left, D=down, F=right
        //   right: I=up, J=left, K=down, L=right
        // Vertical scroll (bottom row, finger-natural — middle=up, index=down):
        //   left:  C=scroll up,  V=scroll down
        //   right: M=scroll down, ,=scroll up
        // MOUSE handoff (mirrors QWRT muscle memory, see mouse_hold_mm):
        //   hold Z or / = momentary MOUSE, release -> QWRT
        //   Z+X or .+/ chord = lock MOUSE, exit lands on QWRT
        // Horizontal scroll — chorded on the 3 vertical-scroll keys,
        // "lean the pair toward the direction" (see combos block):
        //   left hand:  X+C = left, C+V = right (C/V singles = up/down)
        //   right hand: M+, = left, ,+. = right (,/M singles = up/down)
        // App content zoom (Cmd+= / Cmd+-):
        //   Q and Y  = zoom in
        //   T and P  = zoom out
        // Was Cmd+Opt+= / Cmd+Opt+-, the macOS Accessibility screen
        // magnifier, which needed a System Settings opt-in and blew up
        // the whole display. Cmd+= is the app's OWN zoom, so Safari
        // reflows and rescales the page instead. No setup required.
        //
        // NOT pointer-centred, and that is not fixable from here.
        // Safari reaches page magnification only from AppKit gesture
        // events -- WebViewImpl::scrollWheel() never inspects modifiers,
        // and every magnification entry point requires NSEventTypeMagnify,
        // which macOS generates solely from Apple Multi-Touch hardware.
        // There is no consumer HID usage for zoom. Ctrl+wheel is a dead
        // end too: since Safari 15 a pinch EMITS a synthetic ctrl+wheel
        // to page JS as a compat shim, but that is an output, not an
        // input -- feeding one back in just scrolls. Pointer-centred zoom
        // needs host software synthesising a magnify gesture through
        // private CGEvent SPI (ScrollToZoom, Mac Mouse Fix).
        // Desktop / Spaces navigation (macOS Ctrl+Left/Right) — used
        // for macOS Exposé / Spaces switching:
        //   A and H  = prev desktop (LC(LEFT))
        //   G and '  = next desktop (LC(RIGHT))
        // Each hand gets one outer-pinky access (A/') and one inner-
        // index access (H/G), so either hand can swap in either direction
        // without breaking the cursor-move cluster.
        // Browser nav (Cmd+[ / Cmd+]) flanking the up-arrow on each hand:
        //   W = back, R = forward; U = back, O = forward.
        // EXIT: ESC position (left thumb on QWRT — muscle-memory) or
        // re-fire one of the entry combos. The previous Z and / exit
        // keys gave way to horizontal scroll.
        // Clicks on the thumb cluster — no auto-exit, click and scroll freely.
        // All non-bound positions are &none (do nothing) rather than &trans
        // — matches Delta Omega and prevents accidental fall-through to
        // QWRT keys while on MMOVE.
        mousemove_layer {
            label = "MMOVE";
            bindings = <
&kp LG(EQUAL)       &kp LG(LBKT)        &mmv MOVE_UP    &kp LG(RBKT)      &kp LG(MINUS)                           &kp LG(EQUAL)      &kp LG(LBKT)   &mmv MOVE_UP   &kp LG(RBKT)        &kp LG(MINUS)
&kp LC(LEFT)        &mmv MOVE_LEFT      &mmv MOVE_DOWN  &mmv MOVE_RIGHT   &kp LC(RIGHT)                           &kp LC(LEFT)       &mmv MOVE_LEFT &mmv MOVE_DOWN &mmv MOVE_RIGHT     &kp LC(RIGHT)
&mouse_hold_mm      &none               &msc SCRL_UP    &msc SCRL_DOWN    &kp LA(D)                               &kp LA(D)      &msc SCRL_DOWN &msc SCRL_UP   &none               &mouse_hold_mm
&none               &mkp RCLK           &mkp LCLK       &tog MOUSEMOVE    &mkp LCLK        &mkp RCLK              &mkp RCLK      &mkp LCLK                                        &none
            >;
        };
        // ══════════════ Ben Vallack "Piano" profile ══════════════
        // Position map (Ben's 18 keys → Keyball39 positions):
        //   his top trio   → S D F  (11 12 13) / J K L  (16 17 18)
        //   his home quad  → Z X C V (20-23)   / M , . / (26-29)
        //   his 4 thumbs   → 34 35 (left) / 36 37 (right)
        // Everything else is &none. Position 30 and 38 both exit to QWRT.

        ben_layer {
            label = "BEN";
            bindings = <
&mo BEN_MOUSE    &none                &none                 &none                &none                                &none          &none                 &none                 &none                 &mo BEN_MOUSE
&none            &ben_hm_l LCTRL L    &ben_hm_l LALT G      &ben_hm_l LGUI D     &none                                &none          &ben_hm_r RGUI H      &ben_hm_r RALT U      &ben_hm_r RCTRL O     &none
&ben_hl_l BEN_NUM I  &ben_hl_l BEN_S2 S  &ben_hl_l BEN_S1 R  &ben_hl_l BEN_SYS T  &none                                &none          &ben_hl_r BEN_SYS N   &ben_hl_r BEN_S1 E    &ben_hl_r BEN_S2 A    &ben_hl_r BEN_NUM C
&to DEFAULT      &none                &none                 &none                &kp BSPC             &ben_sl BEN_A2U  &ben_sl BEN_A2   &mt LC(LS(LALT)) SPACE                                              &to DEFAULT
            >;
        };

        // The 12 rare letters. Reached by a sticky tap of the right outer
        // thumb (Space key) — one key, then it drops back to BEN by itself.
        ben_a2_layer {
            label = "BEN2";
            bindings = <
&none            &none        &none        &none        &none                                       &none          &none          &none          &none          &none
&none            &kp V        &kp W        &kp M        &none                                       &none          &kp F          &kp SQT        &kp Z          &none
&kp Q            &kp J        &kp P        &kp K        &none                                       &none          &kp B          &kp DOT        &kp X          &kp Y
&to DEFAULT      &none        &none        &none        &trans               &ben_sk LSHFT          &trans         &trans                                           &to DEFAULT
            >;
        };

        ben_sym1_layer {
            label = "BSY1";
            bindings = <
&none            &none        &none        &none        &none                                       &none          &none          &none          &none          &none
&none            &kp LA(N3)   &kp LS(N3)   &kp DLLR     &none                                       &none          &kp LS(COMMA)  &kp LS(DOT)    &kp CARET      &none
&kp GRAVE        &kp TILDE    &kp MINUS    &kp BSLH     &none                                       &none          &kp LBKT       &kp RBKT       &kp PIPE       &kp SLASH
&to DEFAULT      &none        &none        &none        &trans               &trans                 &trans         &trans                                       &to DEFAULT
            >;
        };

        ben_sym2_layer {
            label = "BSY2";
            bindings = <
&none            &none        &none        &none        &none                                       &none          &none          &none          &none          &none
&none            &kp ATSN     &ben_td LA(RBKT) LA(LS(RBKT))  &ben_td LA(LBKT) LA(LS(LBKT))  &none    &none          &kp LPRN       &kp RPRN       &kp SEMI       &none
&kp STAR         &kp PRCNT    &ben_td QMARK EXCL   &kp DQT   &none                                   &none          &kp LBRC       &kp RBRC       &kp AMPS       &kp COLON
&to DEFAULT      &none        &none        &none        &trans               &trans                 &trans         &trans                                       &to DEFAULT
            >;
        };

        ben_num_layer {
            label = "BNUM";
            bindings = <
&none            &none                &none                &none                &none                        &none          &none                &none                &none                &none
&none            &ben_hm_l LCTRL DOT  &ben_hm_l LALT N0    &ben_hm_l LGUI N1    &none                        &none          &ben_hm_r RGUI N2    &ben_hm_r RALT N3    &ben_hm_r RCTRL N4   &none
&kp MINUS        &kp PLUS             &kp N5               &kp N6               &none                        &none          &kp N7               &kp N8               &kp N9               &kp EQUAL
&to DEFAULT      &none                &none                &none                &ben_sr LSHFT BEN   &trans    &trans         &trans                                                        &to DEFAULT
            >;
        };

        // Nav + editing. Backspace lives here: hold V (or M), tap L.
        ben_sys_layer {
            label = "BSYS";
            bindings = <
&none                  &none                &none                 &none                  &none                        &none    &none                &none        &none                          &none
&none                  &kp ESC              &kp LC(LS(TAB))       &kp RC(TAB)            &none                        &none    &ben_td LG(V) LG(C)  &kp UP       &ben_td Q BSPC                 &none
&ben_td LG(GRAVE) TAB  &ben_td HOME DEL     &ben_td END LG(LBKT)  &kp LG(RBKT)           &none                        &none    &ben_td TAB LEFT     &kp DOWN     &ben_td LC(LG(LS(N4))) RIGHT   &kp RET
&to DEFAULT            &none                &none                 &none                  &ben_sr LSHFT BEN   &none     &key_repeat  &kp RGUI                                                    &to DEFAULT
            >;
        };

        // Entered with &to (BEN is dropped underneath), so every unused
        // position here is &none rather than &trans — otherwise they would
        // fall straight through to QWRT.
        ben_bt_layer {
            label = "BBT";
            bindings = <
&none            &none        &none        &none        &none                                       &none          &none          &none          &none          &none
&none            &bt BT_PRV   &bt BT_NXT   &none        &none                                       &none          &none          &none          &none          &none
&bootloader      &none        &none        &none        &none                                       &none          &none          &none          &none          &bt BT_CLR
&to DEFAULT      &none        &none        &none        &to BEN              &none                  &none          &none                                        &to DEFAULT
            >;
        };

        // Capitals of the rare letters — sticky tap of the right INNER
        // thumb (Enter key). Ben leaves the ' slot &trans here, which
        // silently falls through to alpha1 and emits "u"; bound to DQT
        // instead, which is plainly what shift-apostrophe should give.
        ben_a2u_layer {
            label = "BEN2S";
            bindings = <
&none            &none        &none        &none        &none                                       &none          &none          &none          &none          &none
&none            &kp LS(V)    &kp LS(W)    &kp LS(M)    &none                                       &none          &kp LS(F)      &kp DQT        &kp LS(Z)      &none
&kp LS(Q)        &kp LS(J)    &kp LS(P)    &kp LS(K)    &none                                       &none          &kp LS(B)      &kp COMMA      &kp LS(X)      &kp LS(Y)
&to DEFAULT      &none        &none        &none        &trans               &trans                 &trans         &trans                                       &to DEFAULT
            >;
        };
        // Mouse layer for the Ben profile. The trackball already moves the
        // cursor on every layer (the input listener gates only scroll and
        // snipe MODE, never plain motion) — what BEN was missing was
        // clicks, wheel, and a scroll-mode path. Cursor keys mirror the
        // QWRT MMOVE cross so the muscle memory carries over.
        ben_mouse_layer {
            label = "BMOU";
            bindings = <
&trans           &mo BEN_SCRL     &mmv MOVE_UP     &none            &none                            &none          &none          &mmv MOVE_UP     &mo BEN_SCRL   &trans
&none            &mmv MOVE_LEFT   &mmv MOVE_DOWN   &mmv MOVE_RIGHT  &none                            &none          &mmv MOVE_LEFT &mmv MOVE_DOWN   &mmv MOVE_RIGHT  &none
&to BEN          &none            &msc SCRL_UP     &msc SCRL_DOWN   &none                            &none          &msc SCRL_DOWN &msc SCRL_UP     &none          &to BEN
&to DEFAULT      &none            &none            &tog BEN_MOUSE   &mkp LCLK        &mkp MCLK       &mkp RCLK      &mkp LCLK                                      &to DEFAULT
            >;
        };

        // Ball-as-scrollwheel. Listed in scroll-layers in the right
        // overlay, so merely being on this layer turns trackball motion
        // into scrolling. Bindings stay &trans so BEN_MOUSE shows
        // through underneath. Also carries the power-tools row, giving
        // the Ben profile the same hold->hold->tap reflash chain the
        // QWRT profile has (there Z->X->T; here Q->W->T).
        ben_scroll_layer {
            label = "BSCR";
            bindings = <
&trans           &trans           &trans           &sys_reset       &bootloader                      &bootloader    &sys_reset     &trans           &trans         &trans
&trans           &trans           &trans           &trans           &trans                           &trans         &trans         &trans           &trans         &trans
&trans           &trans           &trans           &trans           &trans                           &trans         &trans         &trans           &trans         &trans
&to DEFAULT      &trans           &trans           &trans           &trans           &trans          &trans         &trans                                         &to DEFAULT
            >;
        };
    };
};
